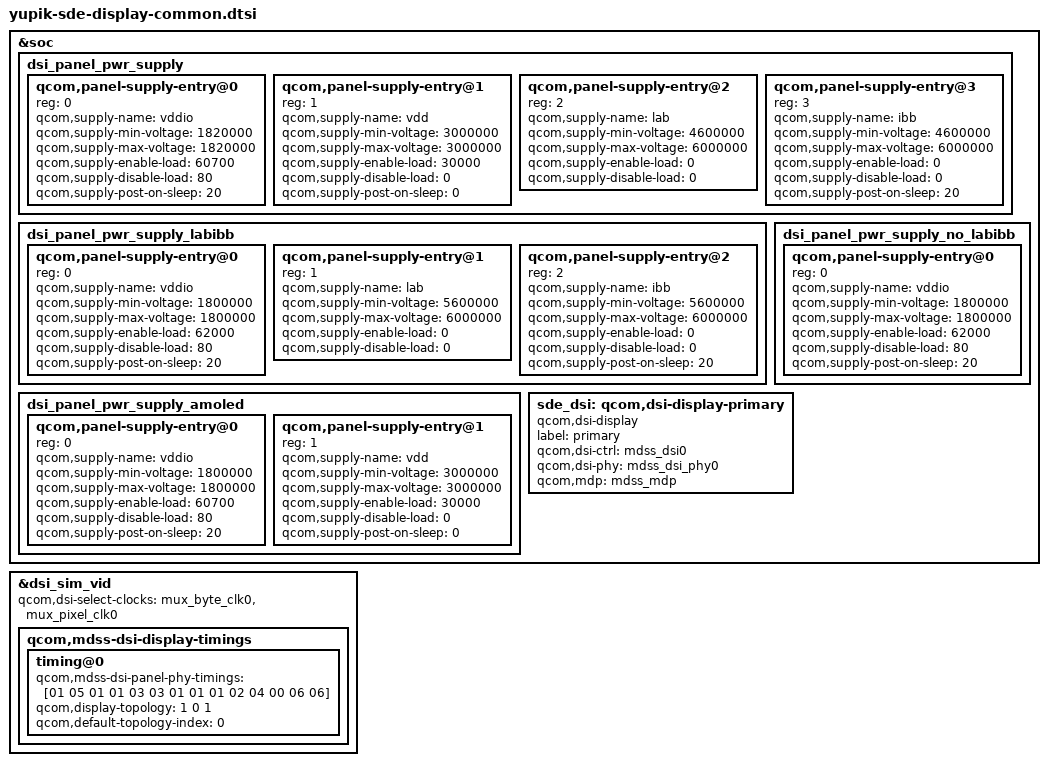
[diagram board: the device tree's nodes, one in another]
#include "dsi-panel-sim-video.dtsi"
#include <dt-bindings/clock/mdss-5nm-pll-clk.h>

&soc {
	dsi_panel_pwr_supply: dsi_panel_pwr_supply {
		#address-cells = <1>;
		#size-cells = <0>;

		qcom,panel-supply-entry@0 {
			reg = <0>;
			qcom,supply-name = "vddio";
			qcom,supply-min-voltage = <1820000>;
			qcom,supply-max-voltage = <1820000>;
			qcom,supply-enable-load = <60700>;
			qcom,supply-disable-load = <80>;
			qcom,supply-post-on-sleep = <20>;
		};

		qcom,panel-supply-entry@1 {
			reg = <1>;
			qcom,supply-name = "vdd";
			qcom,supply-min-voltage = <3000000>;
			qcom,supply-max-voltage = <3000000>;
			qcom,supply-enable-load = <30000>;
			qcom,supply-disable-load = <0>;
			qcom,supply-post-on-sleep = <0>;
		};

		qcom,panel-supply-entry@2 {
			reg = <2>;
			qcom,supply-name = "lab";
			qcom,supply-min-voltage = <4600000>;
			qcom,supply-max-voltage = <6000000>;
			qcom,supply-enable-load = <0>;
			qcom,supply-disable-load = <0>;
		};

		qcom,panel-supply-entry@3 {
			reg = <3>;
			qcom,supply-name = "ibb";
			qcom,supply-min-voltage = <4600000>;
			qcom,supply-max-voltage = <6000000>;
			qcom,supply-enable-load = <0>;
			qcom,supply-disable-load = <0>;
			qcom,supply-post-on-sleep = <20>;
		};
	};

	dsi_panel_pwr_supply_labibb: dsi_panel_pwr_supply_labibb {
		#address-cells = <1>;
		#size-cells = <0>;

		qcom,panel-supply-entry@0 {
			reg = <0>;
			qcom,supply-name = "vddio";
			qcom,supply-min-voltage = <1800000>;
			qcom,supply-max-voltage = <1800000>;
			qcom,supply-enable-load = <62000>;
			qcom,supply-disable-load = <80>;
			qcom,supply-post-on-sleep = <20>;
		};

		qcom,panel-supply-entry@1 {
			reg = <1>;
			qcom,supply-name = "lab";
			qcom,supply-min-voltage = <5600000>;
			qcom,supply-max-voltage = <6000000>;
			qcom,supply-enable-load = <0>;
			qcom,supply-disable-load = <0>;
		};

		qcom,panel-supply-entry@2 {
			reg = <2>;
			qcom,supply-name = "ibb";
			qcom,supply-min-voltage = <5600000>;
			qcom,supply-max-voltage = <6000000>;
			qcom,supply-enable-load = <0>;
			qcom,supply-disable-load = <0>;
			qcom,supply-post-on-sleep = <20>;
		};
	};

	dsi_panel_pwr_supply_amoled: dsi_panel_pwr_supply_amoled {
		#address-cells = <1>;
		#size-cells = <0>;

		qcom,panel-supply-entry@0 {
			reg = <0>;
			qcom,supply-name = "vddio";
			qcom,supply-min-voltage = <1800000>;
			qcom,supply-max-voltage = <1800000>;
			qcom,supply-enable-load = <60700>;
			qcom,supply-disable-load = <80>;
			qcom,supply-post-on-sleep = <20>;
		};

		qcom,panel-supply-entry@1 {
			reg = <1>;
			qcom,supply-name = "vdd";
			qcom,supply-min-voltage = <3000000>;
			qcom,supply-max-voltage = <3000000>;
			qcom,supply-enable-load = <30000>;
			qcom,supply-disable-load = <0>;
			qcom,supply-post-on-sleep = <0>;
		};
	};

	dsi_panel_pwr_supply_no_labibb: dsi_panel_pwr_supply_no_labibb {
		#address-cells = <1>;
		#size-cells = <0>;

		qcom,panel-supply-entry@0 {
			reg = <0>;
			qcom,supply-name = "vddio";
			qcom,supply-min-voltage = <1800000>;
			qcom,supply-max-voltage = <1800000>;
			qcom,supply-enable-load = <62000>;
			qcom,supply-disable-load = <80>;
			qcom,supply-post-on-sleep = <20>;
		};
	};

	sde_dsi: qcom,dsi-display-primary {
		compatible = "qcom,dsi-display";
		label = "primary";

		qcom,dsi-ctrl = <&mdss_dsi0>;
		qcom,dsi-phy = <&mdss_dsi_phy0>;

		qcom,mdp = <&mdss_mdp>;
	};
};

&dsi_sim_vid {
	qcom,dsi-select-clocks = "mux_byte_clk0", "mux_pixel_clk0";
	qcom,mdss-dsi-display-timings {
		timing@0 {
			qcom,mdss-dsi-panel-phy-timings = [01 05 01 01 03 03 01
				01 01 02 04 00 06 06];
			qcom,display-topology = <1 0 1>;
			qcom,default-topology-index = <0>;
		};
	};
};
